AUTOSAR XML (schema 00046)
package /Composition_Lab
  sender receiver interface SRI_Light_Control
    data LightControl: type=uint32
  sender receiver interface SRI_Light_Actuate
    data LightActuateValue: type=uint32
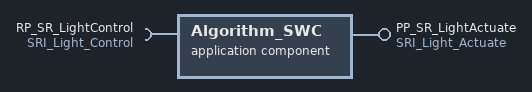
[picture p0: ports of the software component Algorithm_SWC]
  application sw component type Algorithm_SWC
    require port RP_SR_LightControl: required-interface=SRI_Light_Control
    provide port PP_SR_LightActuate: provided-interface=SRI_Light_Actuate
  sensor actuator sw component type LightControlStatus_SWC
    provide port PP_SR_LightControl: provided-interface=SRI_Light_Control
  sensor actuator sw component type LightActuate_SWC
    require port RP_SR_LightActuate: required-interface=SRI_Light_Actuate
  composition sw component type SW_Composite1
    provide port PP_SR_LightActuate_Composite: provided-interface=SRI_Light_Actuate
    component LC_SA_SWC1: type=LightControlStatus_SWC
    component LA_APP_SWC2: type=Algorithm_SWC
    connect LC_SA_SWC1.PP_SR_LightControl -> LA_APP_SWC2.RP_SR_LightControl
    delegate LA_APP_SWC2.PP_SR_LightActuate <-> outer port PP_SR_LightActuate_Composite
  composition sw component type TopLevel_Composite_SWC
    component SW_Composite1_instant: type=SW_Composite1
    component LA_SA_SWC3: type=LightActuate_SWC
    connect SW_Composite1_instant.PP_SR_LightActuate_Composite -> LA_SA_SWC3.RP_SR_LightActuate
